# cyt4dn register map
Vendor: Cypress Semiconductor; Series: cyt4dn; File version: 1.0
CPU: CM7 r0p1, little endian, MPU, FPU, VTOR, 3 interrupt priority bits
Registers are 32-bit, read-write, reset 0x0 unless marked. A register's access mark holds for its fields unless they carry their own. Offsets are from the block's base; [hi:lo] are bit positions; lines under a group give offsets from that group; {n}, {i} and the like mark numbered series; 'fields as' and 'values as' point back to an identical list; <NAME> marks a mode.

## I2S0 — I2S
Base 0x40800000
{0x8000+0x200*i} I2S_STRUCT[{i}] (i=0..3) group — I2S structure
  0x00 I2S_TX_STRUCT group — I2S TX structure
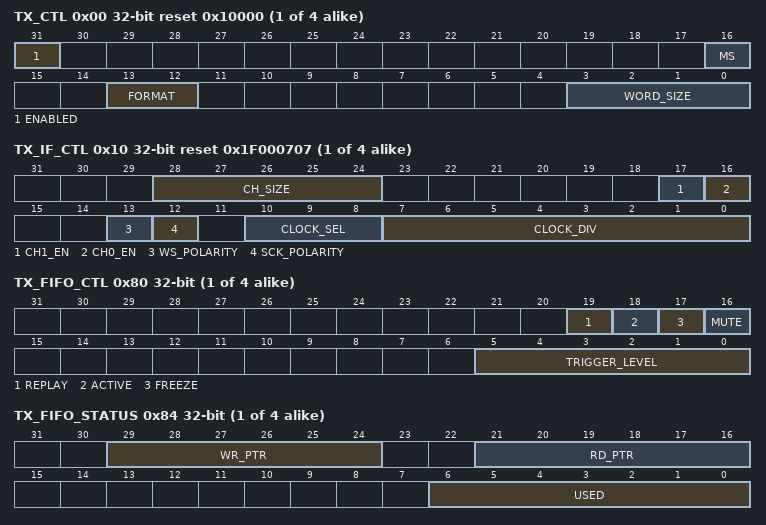
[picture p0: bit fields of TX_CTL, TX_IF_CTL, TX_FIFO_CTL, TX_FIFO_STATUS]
    0x00 TX_CTL reset 0x10000 — TX control
      [31] ENABLED — Transmitter (TX) enable: '0': Disabled. All non-retained MMIO registers (e.g. the TX_FIFO_STATUS and INTR_TX registers) have their fields reset to their default value. '1': Enabled.
      [16] MS — Master/slave setting: '0': Slave. - External transmitter 'i2s_tx_sck_in' and transmitter 'i2s_tx_ws_in'. '1': Master. - Interface clock 'clk_if' is used to generate transmitter 'i2s_tx_sck_out' and transmitter 'i2s_tx_ws_out'.
        0=SLAVE (N/A); 1=MASTER (N/A)
      [13:12] FORMAT — Format: '0': Left-aligned delayed (I2S). '1': Left-aligned. '2': Right-aligned delayed. '3': Right-aligned.
        0=LEFT_DELAYED (N/A); 1=LEFT (N/A); 2=RIGHT_DELAYED (N/A); 3=RIGHT (N/A)
      [3:0] WORD_SIZE — PCM word size: '0': 8 bit. '1': 10 bit. '2': 12 bit. '3': 14 bit. '4': 16 bit. '5': 18 bit. '6': 20 bit. '7': 24 bit. '8': 32 bit. '9'-'15': Undefined.
        0=SIZE_8 (N/A); 1=SIZE_10 (N/A); 2=SIZE_12 (N/A); 3=SIZE_14 (N/A); 4=SIZE_16 (N/A); 5=SIZE_18 (N/A); 6=SIZE_20 (N/A); 7=SIZE_24 (N/A); 8=SIZE_32 (N/A)
    0x10 TX_IF_CTL reset 0x1F000707 — TX interface control
      [28:24] CH_SIZE — Channel size: '0': 1 bit. '1': 2 bits. ... '31': 32 bits. Note: channel size must be greater or equal to the word size.
        0=SIZE_1 (N/A); 1=SIZE_2 (N/A); 31=SIZE_32 (N/A)
      [17] CH1_EN — Channel 1 enable: '0': Disabled. The TX FIFO does not produce channel 1 words and 'i2s_tx_sd_out' is not driven. '1': Enabled.
      [16] CH0_EN — Channel 0 enable: '0': Disabled. The TX FIFO does not produce channel 0 words and 'i2s_tx_sd_out' is not driven. '1': Enabled.
      [13] WS_POLARITY — Word select polarity: '0': Word select signal is used 'as is'. '1': Word select signal is inverted. Note: Used in BOTH master and slave configurations.
      [12] SCK_POLARITY — Clock polarity: '0': Clock signal is used 'as is'. '1': Clock signal is inverted. Note: Used in BOTH master and slave configurations.
      [10:8] CLOCK_SEL — Interface clock 'clk_if' selection: '0': SRSS clock clk_if_srss[0]. '1': SRSS clock clk_if_srss[1]. '2': SRSS clock clk_if_srss[2]. '3': SRSS clock clk_if_srss[3]. '4': Master interface clock 'i2s_tx_mck_in'. '5'-'7': SRSS clock clk_if_srss[0]. Note: intent was to have '5'-'7' as 'clock off'. Current behavior is as described above. May fix this in future IP release.
        {v}=SEL_SRSS_CLOCK{v} (N/A) (v=0..3); 4=SEL_I2S_TX_MCK_IN (N/A)
      [7:0] CLOCK_DIV — Interface clock divider (legal range [1, 255]). The I2S interface 'i2s_tx_sck_out' output signal is defined as clk_if / (CLOCK_DIV + 1). CLOCK_DIV should be set to an odd value ({1, 3, 5, ..., 255}), to ensure a 50/50 percent duty cycle clock. Note: Used in master configuration only.
        0=DIV_BY_1 (N/A); 1=DIV_BY_2 (N/A); 255=DIV_BY_256 (N/A)
    0x20 TX_TEST_CTL — TX test control
      [31] ENABLED — Test mode enable. '0': Disabled. Functional mode. - Transmitter tx_sck_in = IOSS i2s_tx_sck_in. - Transmitter tx_ws_in = IOSS i2s_tx_ws_in. - Receiver rx_sd_in = IOSS i2s_rx_sd_in. '1': Enabled. Test mode (intended to be used with (slave transmitter, master receiver) configuration). - Transmitter tx_sck_in = Receiver i2s_rx_sck_out. - Transmitter tx_ws_in = Receiver i2s_rx_ws_out. - Receiver rx_sd_in = Transmitter i2s_tx_sd_out. Note: TX_TEST_CTL.ENABLED and RX_TEST_CTL.ENABLED should not be set to '1' simultaneously.
        0=FUNCTIONAL (N/A); 1=TEST (N/A)
    0x80 TX_FIFO_CTL — TX FIFO control
      [19] REPLAY — Replay functionality (used when FREEZE is '1' or in case of a FIFO underflow event): '0': HW uses a constant PCM data value of '0'. '1': HW uses the previous PCM data value.
      [18] ACTIVE — Activate functionality: '0': Transmitter off. The FIFO_UNDERFLOW interrupt cause will not be activated. '1': Transmitter on. The FIFO_UNDERFLOW interrupt may be activated (when an underflow event occurs). Note: This functionality is intended for startup purposes.
      [17] FREEZE — Freeze functionality: '0': HW uses TX FIFO data and advances the FIFO read pointer. '1': HW uses a constant PCM data value of '0' or the previous channel PCM data is replayed. Freeze does not advance the FIFO read pointer (the FIFO data is not used). Note: HW ensures that freeze functionality synchronizes on the first channel of a frame to ensure that PCM data of one channel is not misassigned to another channel. As a result, the freeze functionality can be activated at any time. Note: This functionality is intended for debugging purposes.
      [16] MUTE — Mute functionality: '0': HW uses TX FIFO data. '1': HW uses a constant PCM data value of '0'. Mute does advance the FIFO read pointer. Note: HW ensures that mute functionality synchronizes on the first channel of a frame to ensure that either all or none of the frame's channels are muted.
      [5:0] TRIGGER_LEVEL — Trigger level. When the TX FIFO has less entries than the number of this field, a transmitter trigger event is generated: - INTR_TX.FIFO_TRIGGER = (# FIFO entries < TRIGGER_LEVEL)
        0=EMPTY (N/A); 1=USED_1 (N/A); 63=USED_63 (N/A)
    0x84 TX_FIFO_STATUS ro
      [29:24] WR_PTR — TX FIFO write pointer: FIFO location at which a new data is written by the hardware. Note: This functionality is intended for debugging purposes.
      [21:16] RD_PTR — TX FIFO read pointer: FIFO location from which a data is read. Note: This functionality is intended for debugging purposes.
      [6:0] USED — Number of used/occupied entries in the TX FIFO. The field value is in the range [0, 64]. When '0', the FIFO is empty. When '64', the FIFO is full.
        0=EMPTY (N/A); 1=N/A; 64=FULL (N/A)
    0x88 TX_FIFO_WR wo — TX FIFO write
      [31:0] DATA — Data (PCM sample) written to the TX FIFO. Writing adds the data to the TX FIFO; i.e. behavior is similar to that of a PUSH operation (TX_FIFO_STATUS.WR_PTR is incremented and TX_FIFO_STATUS.USED is incremented). The write data (DATA) should be right aligned when it is written to the FIFO entry (data[31:0]): - 8 bit, data[31:0] = DATA[7:0] << 24. - 10 bit, data[31:0] = DATA[9:0] << 22. - 12 bit, data[31:0] = DATA[11:0] << 20. - 14 bit, data[31:0] = DATA[13:0] << 18. - 16 bit, data[31:0] = DATA[15:0] << 16. - 18 bit, data[31:0] = DATA[17:0] << 14. - 20 bit, data[31:0] = DATA[19:0] << 12. - 24 bit, data[31:0] = DATA[23:0] << 8. - 32 bit, data[31:0] = DATA[31:0]. Note: Writing to a full TX FIFO activates INTR.TX_FIFO_OVERFLOW.
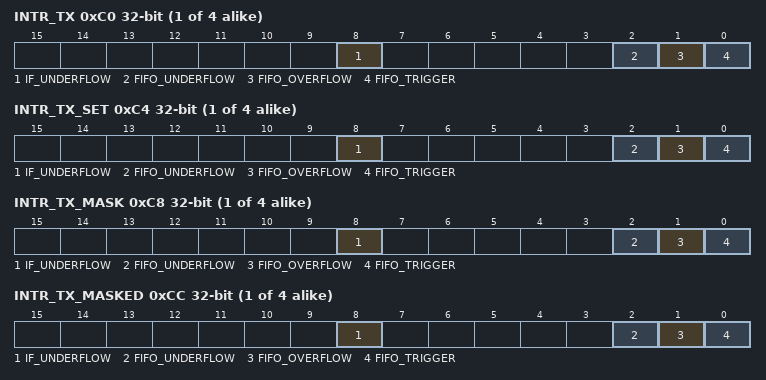
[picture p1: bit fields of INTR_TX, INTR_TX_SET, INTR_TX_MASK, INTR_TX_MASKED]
    0xC0 INTR_TX — Interrupt
      [8] IF_UNDERFLOW — HW sets this field to '1', when PCM samples are not generated in time for the interface logic (interface underflow). This may be an indication that the IP system frequency is too low wrt. the interface frequency (a SW configuration error). The interface underflow is a non-recoverable error and requires SW disabling of the channel (a SW write to INTR_TX.IF_UNDERFLOW does not resolve the interface underflow). Note: This functionality is intended for debug purposes.
      [2] FIFO_UNDERFLOW — HW sets this field to '1', when reading from an (almost) empty TX FIFO (TX_FIFO_STATUS.USED < 'number of enabled channels per frame'). This is referred to as an underflow event. Note: HW ensures that either all or none of the frame's channels are transmitted. In a TX FIFO underflow situation, HW replays previous PCM data or uses a constant PCM data value of '0'.
      [1] FIFO_OVERFLOW — HW sets this field to '1', when writing to a full TX FIFO (TX_FIFO_STATUS.USED is '64').
      [0] FIFO_TRIGGER — HW sets this field to '1', when a TX trigger is generated.
    0xC4 INTR_TX_SET — Interrupt set
      [8] IF_UNDERFLOW — Write this field with '1' to set corresponding INTR_TX field (a write of '0' has no effect).
      [2] FIFO_UNDERFLOW — Write this field with '1' to set corresponding INTR_TX field (a write of '0' has no effect).
      [1] FIFO_OVERFLOW — Write this field with '1' to set corresponding INTR_TX field (a write of '0' has no effect).
      [0] FIFO_TRIGGER — Write this field with '1' to set corresponding INTR_TX field (a write of '0' has no effect).
    0xC8 INTR_TX_MASK — Interrupt mask
      [8] IF_UNDERFLOW — Mask for corresponding field in INTR_TX register.
      [2] FIFO_UNDERFLOW — Mask for corresponding field in INTR_TX register.
      [1] FIFO_OVERFLOW — Mask for corresponding field in INTR_TX register.
      [0] FIFO_TRIGGER — Mask for corresponding field in INTR_TX register.
    0xCC INTR_TX_MASKED ro — Interrupt masked
      [8] IF_UNDERFLOW — Logical AND of corresponding INTR_TX and INTR_TX_MASK fields.
      [2] FIFO_UNDERFLOW — Logical AND of corresponding INTR_TX and INTR_TX_MASK fields.
      [1] FIFO_OVERFLOW — Logical AND of corresponding INTR_TX and INTR_TX_MASK fields.
      [0] FIFO_TRIGGER — Logical AND of corresponding INTR_TX and INTR_TX_MASK fields.
  0x100 I2S_RX_STRUCT group — I2S RX structure
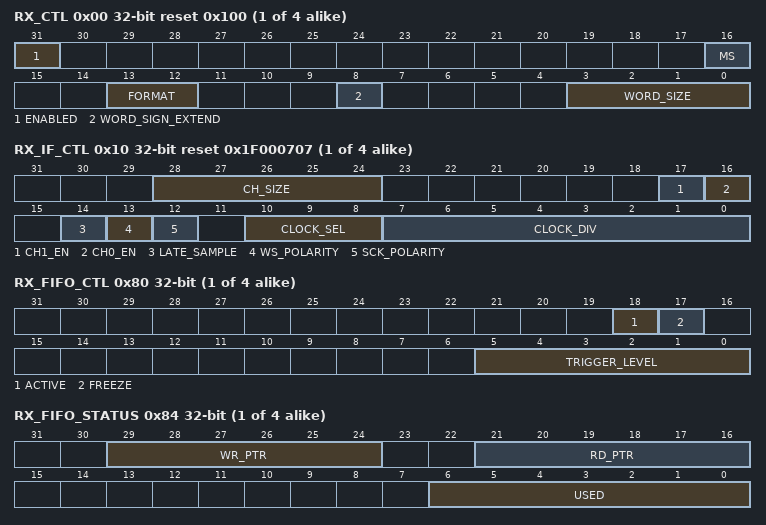
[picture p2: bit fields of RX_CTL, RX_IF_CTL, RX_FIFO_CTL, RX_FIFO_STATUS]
    0x00 RX_CTL reset 0x100 — RX control
      [31] ENABLED — Receiver (RX) enable: '0': Disabled. All non-retained MMIO registers (e.g. the RX_FIFO_STATUS and INTR_RX registers) have their fields reset to their default value. '1': Enabled.
      [16] MS — Master/slave setting: '0': Slave. - External receiver 'i2s_rx_sck_in' and receiver 'i2s_rx_ws_in'. '1': Master. - Interface clock 'clk_if_srss' is used to generate receiver 'i2s_rx_sck_out' and receiver 'i2s_rx_ws_out'.
        0=SLAVE (N/A); 1=MASTER (N/A)
      [13:12] FORMAT — Format: '0': Left-aligned delayed (I2S). '1': Left-aligned. '2': Right-aligned delayed. '3': Right-aligned.
        values as I2S_STRUCT[0].I2S_TX_STRUCT.TX_CTL.FORMAT
      [8] WORD_SIGN_EXTEND — Word extension: '0': zero extension. '1': sign extension.
        0=ZERO_EXTEND (N/A); 1=SIGN_EXTEND (N/A)
      [3:0] WORD_SIZE — PCM word size: '0': 8 bit. '1': 10 bit. '2': 12 bit. '3': 14 bit. '4': 16 bit. '5': 18 bit. '6': 20 bit. '7': 24 bit. '8': 32 bit. '9'-'15': Undefined.
        values as I2S_STRUCT[0].I2S_TX_STRUCT.TX_CTL.WORD_SIZE
    0x10 RX_IF_CTL reset 0x1F000707 — RX interface control
      [28:24] CH_SIZE — Channel size: '0': 1 bit. '1': 2 bits. ... '31': 32 bits. Note: channel size must be greater or equal to the word size.
        0=SIZE_1 (N/A); 1=SIZE_2 (N/A); 31=SIZE_32 (N/A)
      [17] CH1_EN — Channel 1 enable: '0': Disabled. The RX FIFO does not consume channel 1 words and the transmitted channel 1 words on the interface are not driven (the output enable of the 'i2s_tx_sd_out' output signal is not driven). '1': Enabled.
      [16] CH0_EN — Channel 0 enable: '0': Disabled. The RX FIFO does not consume channel 0 words and the transmitted channel 0 words on the interface are not driven (the output enable of the 'i2s_tx_sd_out' output signal is not driven). '1': Enabled.
      [14] LATE_SAMPLE — Interface late sample sample delay: Slave configuration (RX_CTL.MS is '0'). '0': Sample PCM bit value on rising edge (SCK_POLARITY is '0') or falling edge (SCK_POLARITY is '1') of receiver 'rx_sck_in'. '1': Sample PCM bit value on falling edge (SCK_POLARITY is '0') or rising edge (SCK_POLARITY is '1') of receiver 'rx_sck_in' (half a cycle delay). Master configuration (RX_CTL.MS is '1'). '0': Sample PCM bit value on rising edge (SCK_POLARITY is '0') or falling edge (SCK_POLARITY is '1') of receiver 'rx_sck_out'. '1': Sample PCM bit value on falling edge (SCK_POLARITY is '0') or rising edge (SCK_POLARITY is '1') of receiver 'rx_sck_out' (half a cycle delay). Note: This field can be set to '1' when the roundtrip delay is large (typically) in a master receiver configuration.
        0=RISING (N/A); 1=FALLING (N/A)
      [13] WS_POLARITY — Word select polarity: '0': Word select signal is used 'as is'. '1': Word select signal is inverted. Note: Applies in BOTH master and slave configurations.
      [12] SCK_POLARITY — Clock polarity: '0': Clock signal is used 'as is'. '1': Clock signal is inverted. Note: Used in BOTH master and slave configurations.
      [10:8] CLOCK_SEL — Interface clock 'clk_if' selection: '0': SRSS clock clk_if_srss[0]. '1': SRSS clock clk_if_srss[1]. '2': SRSS clock clk_if_srss[2]. '3': SRSS clock clk_if_srss[3]. '4': Master interface clock 'i2s_rx_mck_in'. '5'-'7': SRSS clock clk_if_srss[0]. Note: intent was to have '5'-'7' as 'clock off'. Current behavior is as described above. May fix this in future IP release.
        {v}=SEL_SRSS_CLOCK{v} (N/A) (v=0..3); 4=SEL_I2S_RX_MCK_IN (N/A)
      [7:0] CLOCK_DIV — Interface clock divider (legal range [1, 255]). The I2S interface 'i2s_rx_sck_out' output signal is defined as clk_if / (CLOCK_DIV + 1). CLOCK_DIV should be set to an odd value ({1, 3, 5, ..., 255}), to ensure a 50/50 percent duty cycle clock. Note: Used in master configuration only.
        0=DIV_BY_1 (N/A); 1=DIV_BY_2 (N/A); 255=DIV_BY_256 (N/A)
    0x20 RX_TEST_CTL — RX test control
      [31] ENABLED — Test mode enable. '0': Disabled. Functional mode. - Receiver rx_sck_in = IOSS i2s_rx_sck_in. - Receiver rx_ws_in = IOSS i2s_rx_ws_in. - Receiver rx_sd_in = IOSS i2s_rx_sd_in. '1': Enabled. Test mode (intended to be used with (master transmitter, slave receiver) configuration). - Receiver rx_sck_in = Transmitter i2s_tx_sck_out. - Receiver rx_ws_in = Transmitter i2s_tx_ws_out. - Receiver rx_sd_in = Transmitter i2s_tx_sd_out. Note: TX_TEST_CTL.ENABLED and RX_TEST_CTL.ENABLED should not be set to '1' simultaneously.
        0=FUNCTIONAL (N/A); 1=TEST (N/A)
    0x80 RX_FIFO_CTL — RX FIFO control
      [18] ACTIVE — Activate functionality: '0': Receiver off. The FIFO_OVERFLOW interrupt cause will not be activated. '1': Receiver on. The FIFO_OVERFLOW interrupt may be activated (when an overflow event occurs). Note: This functionality is intended for stopping purposes.
      [17] FREEZE — Freeze functionality: '0': HW writes to the RX FIFO and advances the FIFO write pointer. '1': HW writes from the RX FIFO have no effect: freeze will not advance the FIFO write pointer. Note: HW ensures that freeze functionality synchronizes on the first channel of a frame to ensure that PCM data of one channel is not misassigned to another channel. As a result, the freeze functionality can be activated at any time. Note: This functionality is intended for debugging purposes.
      [5:0] TRIGGER_LEVEL — Trigger level. When the RX FIFO has more entries than the number of this field, a receiver trigger event is generated: - INTR_RX.FIFO_TRIGGER = (# FIFO entries > TRIGGER_LEVEL)
        0=EMPTY (N/A); 1=USED_1 (N/A); 63=USED_63 (N/A)
    0x84 RX_FIFO_STATUS ro
      [29:24] WR_PTR — RX FIFO write pointer: FIFO location at which a new data is written by the hardware. Note: This functionality is intended for debugging purposes.
      [21:16] RD_PTR — RX FIFO read pointer: FIFO location from which a data is read. Note: This functionality is intended for debugging purposes.
      [6:0] USED — Number of used/occupied entries in the RX FIFO. The field value is in the range [0, 64]. When '0', the FIFO is empty. When '64', the FIFO is full.
        0=EMPTY (N/A); 1=N/A; 64=FULL (N/A)
    0x88 RX_FIFO_RD ro — RX FIFO read
      [31:0] DATA — Data (PCM sample) read from the RX FIFO. Reading removes the data from the RX FIFO; i.e. behavior is similar to that of a POP operation (RX_FIFO_STATUS.RD_PTR is incremented and RX_FIFO_STATUS.USED is decremented). The read data (DATA) is right aligned (unused bit positions follow the specified sign extension per RX_CTL.WORD_SIGN_EXTEND) when it is read from the FIFO entry (data[31:0]): - 8 bit, DATA[7:0] = data[31:24]. - 10 bit, DATA[9:0] = data[31:22]. - 12 bit, DATA[11:0] = data[31:20]. - 14 bit, DATA[13:0] = data[31:18]. - 16 bit, DATA[15:0] = data[31:16]. - 18 bit, DATA[17:0] = data[31:14]. - 20 bit, DATA[19:0] = data[31:12]. - 24 bit, DATA[23:0] = data[31:8]. - 32 bit, DATA[31:0] = data[31:0]. Note: Reading from an empty RX FIFO activates INTR_RX.FIFO_UNDERFLOW.
    0x8C RX_FIFO_RD_SILENT ro — RX FIFO silent read
      [31:0] DATA
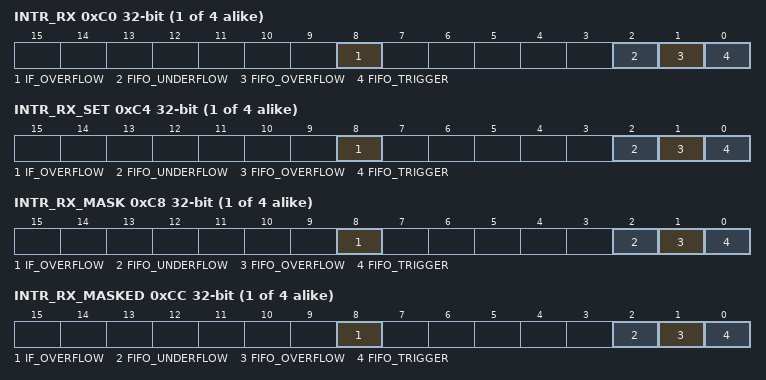
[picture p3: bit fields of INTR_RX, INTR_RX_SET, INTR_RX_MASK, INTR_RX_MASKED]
    0xC0 INTR_RX — Interrupt
      [8] IF_OVERFLOW — HW sets this field to '1', when PCM samples are generated too fast by the interface logic (interface overflow). This may be an indication that the IP system frequency is too low wrt. the interface frequency (a SW configuration error). The interface overflow is a non-recoverable error and requires SW disabling of the channel (a SW write to INTR_RX.IF_OVERFLOW does not resolve the interface underflow). Note: This functionality is intended for debug purposes.
      [2] FIFO_UNDERFLOW — HW sets this field to '1', when reading from an empty RX FIFO (RX_FIFO_STATUS.USED is '0').
      [1] FIFO_OVERFLOW — HW sets this field to '1', when writing to a (almost) full RX FIFO (64 -RX_FIFO_STATUS.USED < 'number of enabled channels per frame'). This is referred to as an overflow event. Note: HW ensures that either all or none of the frame's channels are received. In a RX FIFO overflow situation, HW discards received PCM data values.
      [0] FIFO_TRIGGER — HW sets this field to '1', when a RX trigger is generated.
    0xC4 INTR_RX_SET — Interrupt set
      [8] IF_OVERFLOW — Write this field with '1' to set corresponding INTR_RX field (a write of '0' has no effect).
      [2] FIFO_UNDERFLOW — Write this field with '1' to set corresponding INTR_RX field (a write of '0' has no effect).
      [1] FIFO_OVERFLOW — Write this field with '1' to set corresponding INTR_RX field (a write of '0' has no effect).
      [0] FIFO_TRIGGER — Write this field with '1' to set corresponding INTR_RX field (a write of '0' has no effect).
    0xC8 INTR_RX_MASK — Interrupt mask
      [8] IF_OVERFLOW — Mask for corresponding field in INTR_RX register.
      [2] FIFO_UNDERFLOW — Mask for corresponding field in INTR_RX register.
      [1] FIFO_OVERFLOW — Mask for corresponding field in INTR_RX register.
      [0] FIFO_TRIGGER — Mask for corresponding field in INTR_RX register.
    0xCC INTR_RX_MASKED ro — Interrupt masked
      [8] IF_OVERFLOW — Logical AND of corresponding INTR_RX and INTR_RX_MASK fields.
      [2] FIFO_UNDERFLOW — Logical AND of corresponding INTR_RX and INTR_RX_MASK fields.
      [1] FIFO_OVERFLOW — Logical AND of corresponding INTR_RX and INTR_RX_MASK fields.
      [0] FIFO_TRIGGER — Logical AND of corresponding INTR_RX and INTR_RX_MASK fields.

## Notices in the file
Copyright 2016-2019, Cypress Semiconductor Corporation.  All rights reserved.
You may use this file only in accordance with the license, terms, conditions,
disclaimers, and limitations in the end user license agreement accompanying
the software package with which this file was provided.
